VERSION ""

NS_ :

BS_:

BU_:
VAL_TABLE_ FMI 22 "Data Drifted Low" 21 "Data Drifted High" 20 "Received Network Data In Error" 0 "Above normal (most severe)" 1 "Below normal (most severe)" 2 "Data erratic" 3 "Voltage above normal" 4 "Voltage below normal" 5 "Current below normal" 6 "Current above normal" 7 "Mechanical system not responding" 8 "Abnormal frequency" 9 "Abnormal update rate" 10 "Abnormal rate of change" 11 "Root cause not known" 12 "Bad intelligent device" 13 "Out of calibration" 14 "Special intstructions" 15 "Above normal (least severe)" 16 "Above normal (moderately severe)" 17 "Below normal (least severe)" 18 "Below normal (moderately severe)" 19 "Received network data in error" 31 "Condition Exists" ;

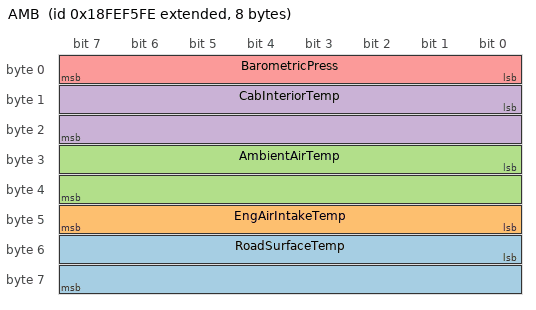
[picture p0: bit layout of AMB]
BO_ 2566845950 AMB: 8 Vector__XXX
 SG_ RoadSurfaceTemp : 48|16@1+ (0.03125,-273) [-273|1734.96875] "°C" Vector__XXX
 SG_ EngAirIntakeTemp : 40|8@1+ (1,-40) [-40|210] "°C" Vector__XXX
 SG_ AmbientAirTemp : 24|16@1+ (0.03125,-273) [-273|1734.96875] "�C" Vector__XXX
 SG_ CabInteriorTemp : 8|16@1+ (0.03125,-273) [-273|1734.96875] "°C" Vector__XXX
 SG_ BarometricPress : 0|8@1+ (0.5,0) [0|125] "kPa" Vector__XXX

CM_ "$File: //depot/auto/dbc/Software_Modules/Thermal_System/j1939_HVAC/0.1.1.0/j1939_HVAC.dbc $
$Change: 215798 $
$DateTime: 2024/08/14 11:20:44 $
$Revision: #1 $";
CM_ BO_ 2566845950 "Ambient Conditions";
CM_ SG_ 2566845950 RoadSurfaceTemp "Indicated temperature of road surface over which vehicle is operating.";
CM_ SG_ 2566845950 EngAirIntakeTemp "Temperature of air entering vehicle air induction system.";
CM_ SG_ 2566845950 AmbientAirTemp "Temperature of air surrounding vehicle.";
CM_ SG_ 2566845950 CabInteriorTemp "Temperature of air inside the part of the vehicle that encloses the driver and vehicle operating controls.

Note: See also SPN 1691.  SPN 1662 is an additional diagnostic SPN associated with cab temperature.";
CM_ SG_ 2566845950 BarometricPress "Absolute air pressure of the atmosphere.";
BA_DEF_  "DBName" STRING ;
BA_DEF_ SG_  "SigType" ENUM  "Default","Range","RangeSigned","ASCII","Discrete","Control","ReferencePGN","DTC","StringDelimiter","StringLength","StringLengthControl","MessageCounter","MessageChecksum";
BA_DEF_ SG_  "GenSigSendType" ENUM  "Cyclic","OnWrite","OnWriteWithRepetition","OnChange","OnChangeWithRepetition","IfActive","IfActiveWithRepetition","NoSigSendType";
BA_DEF_ SG_  "GenSigILSupport" ENUM  "No","Yes";
BA_DEF_ SG_  "GenSigEVName" STRING ;
BA_DEF_ SG_  "SPN" INT 0 524287;
BA_DEF_ BO_  "GenMsgILSupport" ENUM  "No","Yes";
BA_DEF_ BO_  "GenMsgRequestable" INT 0 1;
BA_DEF_ BO_  "GenMsgSendType" ENUM  "cyclic","NotUsed","NotUsed","NotUsed","NotUsed","NotUsed","NotUsed","IfActive","noMsgSendType";
BA_DEF_ BO_  "VFrameFormat" ENUM  "StandardCAN","ExtendedCAN","reserved","J1939PG";
BA_DEF_ BO_  "GenMsgCycleTime" INT 0 3600000;
BA_DEF_ BO_  "Producer" STRING ;
BA_DEF_ BU_  "NmStationAddress" INT 0 255;
BA_DEF_  "SAE_J1939_DA_SpecVersion" STRING ;
BA_DEF_  "SAE_J1939_81_SpecVersion" STRING ;
BA_DEF_  "DatabaseVersion" STRING ;
BA_DEF_  "BusType" STRING ;
BA_DEF_  "ProtocolType" STRING ;
BA_DEF_  "SAE_J1939_75_SpecVersion" STRING ;
BA_DEF_  "SAE_J1939_21_SpecVersion" STRING ;
BA_DEF_  "SAE_J1939_73_SpecVersion" STRING ;
BA_DEF_  "SAE_J1939_71_SpecVersion" STRING ;
BA_DEF_DEF_  "DBName" "j1939_HVAC";
BA_DEF_DEF_  "SigType" "Default";
BA_DEF_DEF_  "GenSigSendType" "NoSigSendType";
BA_DEF_DEF_  "GenSigILSupport" "Yes";
BA_DEF_DEF_  "GenSigEVName" "Env@Nodename_@Signame";
BA_DEF_DEF_  "SPN" 0;
BA_DEF_DEF_  "GenMsgILSupport" "Yes";
BA_DEF_DEF_  "GenMsgRequestable" 1;
BA_DEF_DEF_  "GenMsgSendType" "noMsgSendType";
BA_DEF_DEF_  "VFrameFormat" "J1939PG";
BA_DEF_DEF_  "GenMsgCycleTime" 0;
BA_DEF_DEF_  "Producer" "TMS";
BA_DEF_DEF_  "NmStationAddress" 254;
BA_DEF_DEF_  "SAE_J1939_DA_SpecVersion" "";
BA_DEF_DEF_  "SAE_J1939_81_SpecVersion" "";
BA_DEF_DEF_  "DatabaseVersion" "";
BA_DEF_DEF_  "BusType" "";
BA_DEF_DEF_  "ProtocolType" "";
BA_DEF_DEF_  "SAE_J1939_75_SpecVersion" "";
BA_DEF_DEF_  "SAE_J1939_21_SpecVersion" "";
BA_DEF_DEF_  "SAE_J1939_73_SpecVersion" "";
BA_DEF_DEF_  "SAE_J1939_71_SpecVersion" "";
BA_ "SAE_J1939_71_SpecVersion" "2012-10";
BA_ "SAE_J1939_73_SpecVersion" "2012-10";
BA_ "SAE_J1939_21_SpecVersion" "2006-10";
BA_ "SAE_J1939_75_SpecVersion" "2012-05";
BA_ "ProtocolType" "J1939";
BA_ "BusType" "CAN";
BA_ "DatabaseVersion" "8.5";
BA_ "SAE_J1939_81_SpecVersion" "2012-05";
BA_ "SAE_J1939_DA_SpecVersion" "2015-01";
BA_ "DBName" "J1939_HVAC";
BA_ "GenMsgCycleTime" BO_ 2566845950 1000;
BA_ "GenMsgSendType" BO_ 2566845950 0;
BA_ "SPN" SG_ 2566845950 RoadSurfaceTemp 79;
BA_ "SigType" SG_ 2566845950 RoadSurfaceTemp 1;
BA_ "SPN" SG_ 2566845950 EngAirIntakeTemp 172;
BA_ "SigType" SG_ 2566845950 EngAirIntakeTemp 1;
BA_ "SPN" SG_ 2566845950 AmbientAirTemp 171;
BA_ "SigType" SG_ 2566845950 AmbientAirTemp 1;
BA_ "SPN" SG_ 2566845950 CabInteriorTemp 170;
BA_ "SigType" SG_ 2566845950 CabInteriorTemp 1;
BA_ "SPN" SG_ 2566845950 BarometricPress 108;
BA_ "SigType" SG_ 2566845950 BarometricPress 1;
